# STM32C071xx register map
File version: 1.0
Registers are 32-bit, read-write, reset 0x0 unless marked. A register's access mark holds for its fields unless they carry their own. Offsets are from the block's base; [hi:lo] are bit positions; {n}, {i} and the like mark numbered series.

## SYSCFG — System configuration controller
Base 0x40010000
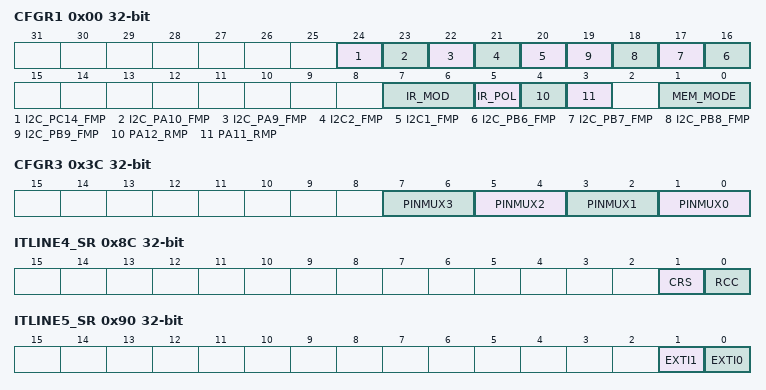
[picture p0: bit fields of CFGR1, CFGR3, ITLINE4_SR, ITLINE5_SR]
0x00 CFGR1 — SYSCFG configuration register 1
  [24] I2C_PC14_FMP — Enable Fast Mode Plus on PC14
  [23] I2C_PA10_FMP — Enable Fast Mode Plus on PA10
  [22] I2C_PA9_FMP — Enable Fast Mode Plus on PA9
  [21] I2C2_FMP — Enable I2C2 Fast mode plus
  [20] I2C1_FMP — Enable Fast Mode Plus on PB10, PB11, PF6 and PF7
  [n+10] I2C_PB{n}_FMP (n=6..9) — I2C PB{n} Fast mode plus
  [7:6] IR_MOD — IRDA Modulation Envelope signal source selection
    0=TIM16 (00: Timer16 is selected as IRDA Modulation envelope source); 1=USART1 (01: USART1 is selected as IRDA Modulation envelope source); 2=USART2 (10: USART2 is selected as IRDA Modulation envelope source)
  [5] IR_POL — IROut Polarity Selection
    1=INVERTED (1: Output of IRDA (IROut) inverted); 0=NOT_INVERTED (0: Output of IRDA (IROut) not inverted)
  [4] PA12_RMP — PA12 Remap
  [3] PA11_RMP — PA11 Remap
  [1:0] MEM_MODE — SYSCFG_Memory Remap Config
    0=FLASH (Main Flash memory mapped at 0x00000000); 1=SYSTEMFLASH (System Flash memory mapped at 0x00000000); 3=SRAM (Embedded SRAM mapped at 0x00000000)
0x18 CFGR2 — SYSCFG configuration register 2
  [0] CLL — Enables and locks the LOCKUP (Hardfault) output of CortexM0 with Break Input of TIMER1/16/17
0x3C CFGR3 — SYSCFG configuration register 3
  [2n+1:2n] PINMUX{n} (n=0..3) — Pin GPIO multiplexer {n}
0x80 ITLINE1_SR — SYSCFG configuration IT_LINE register
  [1] PVM_VDDIO2_OUT — PVM_VDDIO2_OUT interrupt
0x84 ITLINE2_SR — SYSCFG configuration IT_LINE register
  [1] RTC — RTC interrupt
0x88 ITLINE3_SR — SYSCFG configuration IT_LINE register
  [1] FLASH_ITF — FLASH ITF interrupt
0x8C ITLINE4_SR — SYSCFG configuration IT_LINE register
  [1] CRS — CRS interrupt
  [0] RCC — RCC interrupt
0x90 ITLINE5_SR — SYSCFG configuration IT_LINE register
  [1] EXTI1 — External Interrupt 1
  [0] EXTI0 — External Interrupt 0
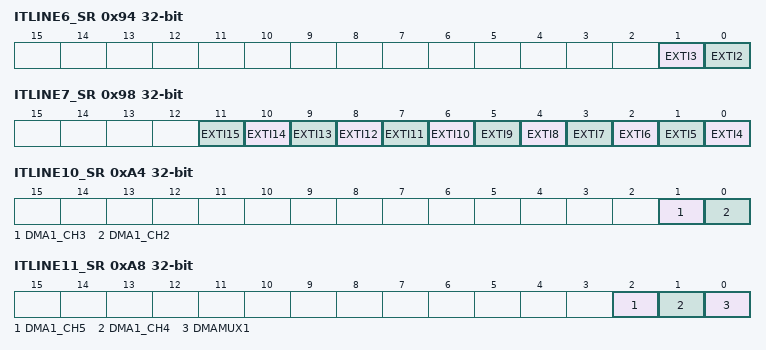
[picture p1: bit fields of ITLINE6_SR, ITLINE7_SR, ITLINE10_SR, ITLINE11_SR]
0x94 ITLINE6_SR — SYSCFG configuration IT_LINE register
  [1] EXTI3 — External Interrupt 3
  [0] EXTI2 — External Interrupt 2
0x98 ITLINE7_SR — SYSCFG configuration IT_LINE register
  [n-4] EXTI{n} (n=4..15) — External Interrupt {n}
0x9C ITLINE8_SR — SYSCFG configuration IT_LINE register
  [0] USB — USB Interrupt
0xA0 ITLINE9_SR — SYSCFG configuration IT_LINE register
  [0] DMA1_CH1 — DMA1 Channel 1 Interrupt
0xA4 ITLINE10_SR — SYSCFG configuration IT_LINE register
  [1] DMA1_CH3 — DMA1 Channel 3 Interrupt
  [0] DMA1_CH2 — DMA1 Channel 2 Interrupt
0xA8 ITLINE11_SR — SYSCFG configuration IT_LINE register
  [2] DMA1_CH5 — DMA1 CH5 Interrupt
  [1] DMA1_CH4 — DMA1 CH4 Interrupt
  [0] DMAMUX1 — DMAMUX Interrupt
0xAC ITLINE12_SR — SYSCFG configuration IT_LINE register
  [0] ADC — ADC Interrupt
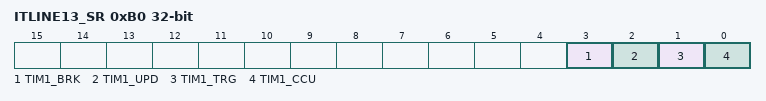
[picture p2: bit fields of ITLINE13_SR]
0xB0 ITLINE13_SR — SYSCFG configuration IT_LINE register
  [3] TIM1_BRK — TIM1 BRK Interrupt
  [2] TIM1_UPD — TIM1 UPD Interrupt
  [1] TIM1_TRG — TIM1 TRG Interrupt
  [0] TIM1_CCU — TIM1 CCU Interrupt
0xB4 ITLINE14_SR — SYSCFG configuration IT_LINE register
  [0] TIM1_CC — TIM1 CC Interrupt
0xB8 ITLINE15_SR — SYSCFG configuration IT_LINE register
  [0] TIM2 — TIM2 GLB Interrupt
0xBC ITLINE16_SR — SYSCFG configuration IT_LINE register
  [0] TIM3_GLB — TIM3 GLB Interrupt
0xC0 IT_LINE_SR16 — SYSCFG configuration IT_LINE register
  [1] PVM_VDDIO2_OUT — PVM_VDDIO2_OUT interrupt
0xC4 IT_LINE_SR17 — SYSCFG configuration IT_LINE register
  [1] PVM_VDDIO2_OUT — PVM_VDDIO2_OUT interrupt
0xC8 ITLINE19_SR — SYSCFG configuration IT_LINE register
  [0] TIM14_GLB — TIM14 GLB Interrupt
0xCC IT_LINE_SR19 — SYSCFG configuration IT_LINE register
  [1] PVM_VDDIO2_OUT — PVM_VDDIO2_OUT interrupt
0xD0 ITLINE21_SR — SYSCFG configuration IT_LINE register
  [0] TIM16_GLB — TIM16 GLB Interrupt
0xD4 ITLINE22_SR — SYSCFG configuration IT_LINE register
  [0] TIM17_GLB — TIM17 GLB Interrupt
0xD8 ITLINE23_SR — SYSCFG configuration IT_LINE register
  [0] I2C1_GLB — I2C1 GLB Interrupt
0xDC ITLINE24_SR — SYSCFG configuration IT_LINE register
  [0] I2C2_GLB — I2C2 GLB Interrupt -> exti[22]
0xE0 ITLINE25_SR — SYSCFG configuration IT_LINE register
  [0] SPI1 — SPI1 Interrupt
0xE4 ITLINE26_SR — SYSCFG configuration IT_LINE register
  [0] SPI2 — SPI2 Interrupt
0xE8 ITLINE27_SR — SYSCFG configuration IT_LINE register
  [0] USART1_GLB — USART1 GLB Interrupt
0xEC ITLINE28_SR — SYSCFG configuration IT_LINE register
  [0] USART2_GLB — USART2 GLB Interrupt
{0x80+4i} IT_LINE_SR{i} (i=28..31) — SYSCFG configuration IT_LINE register
  [1] PVM_VDDIO2_OUT — PVM_VDDIO2_OUT interrupt
